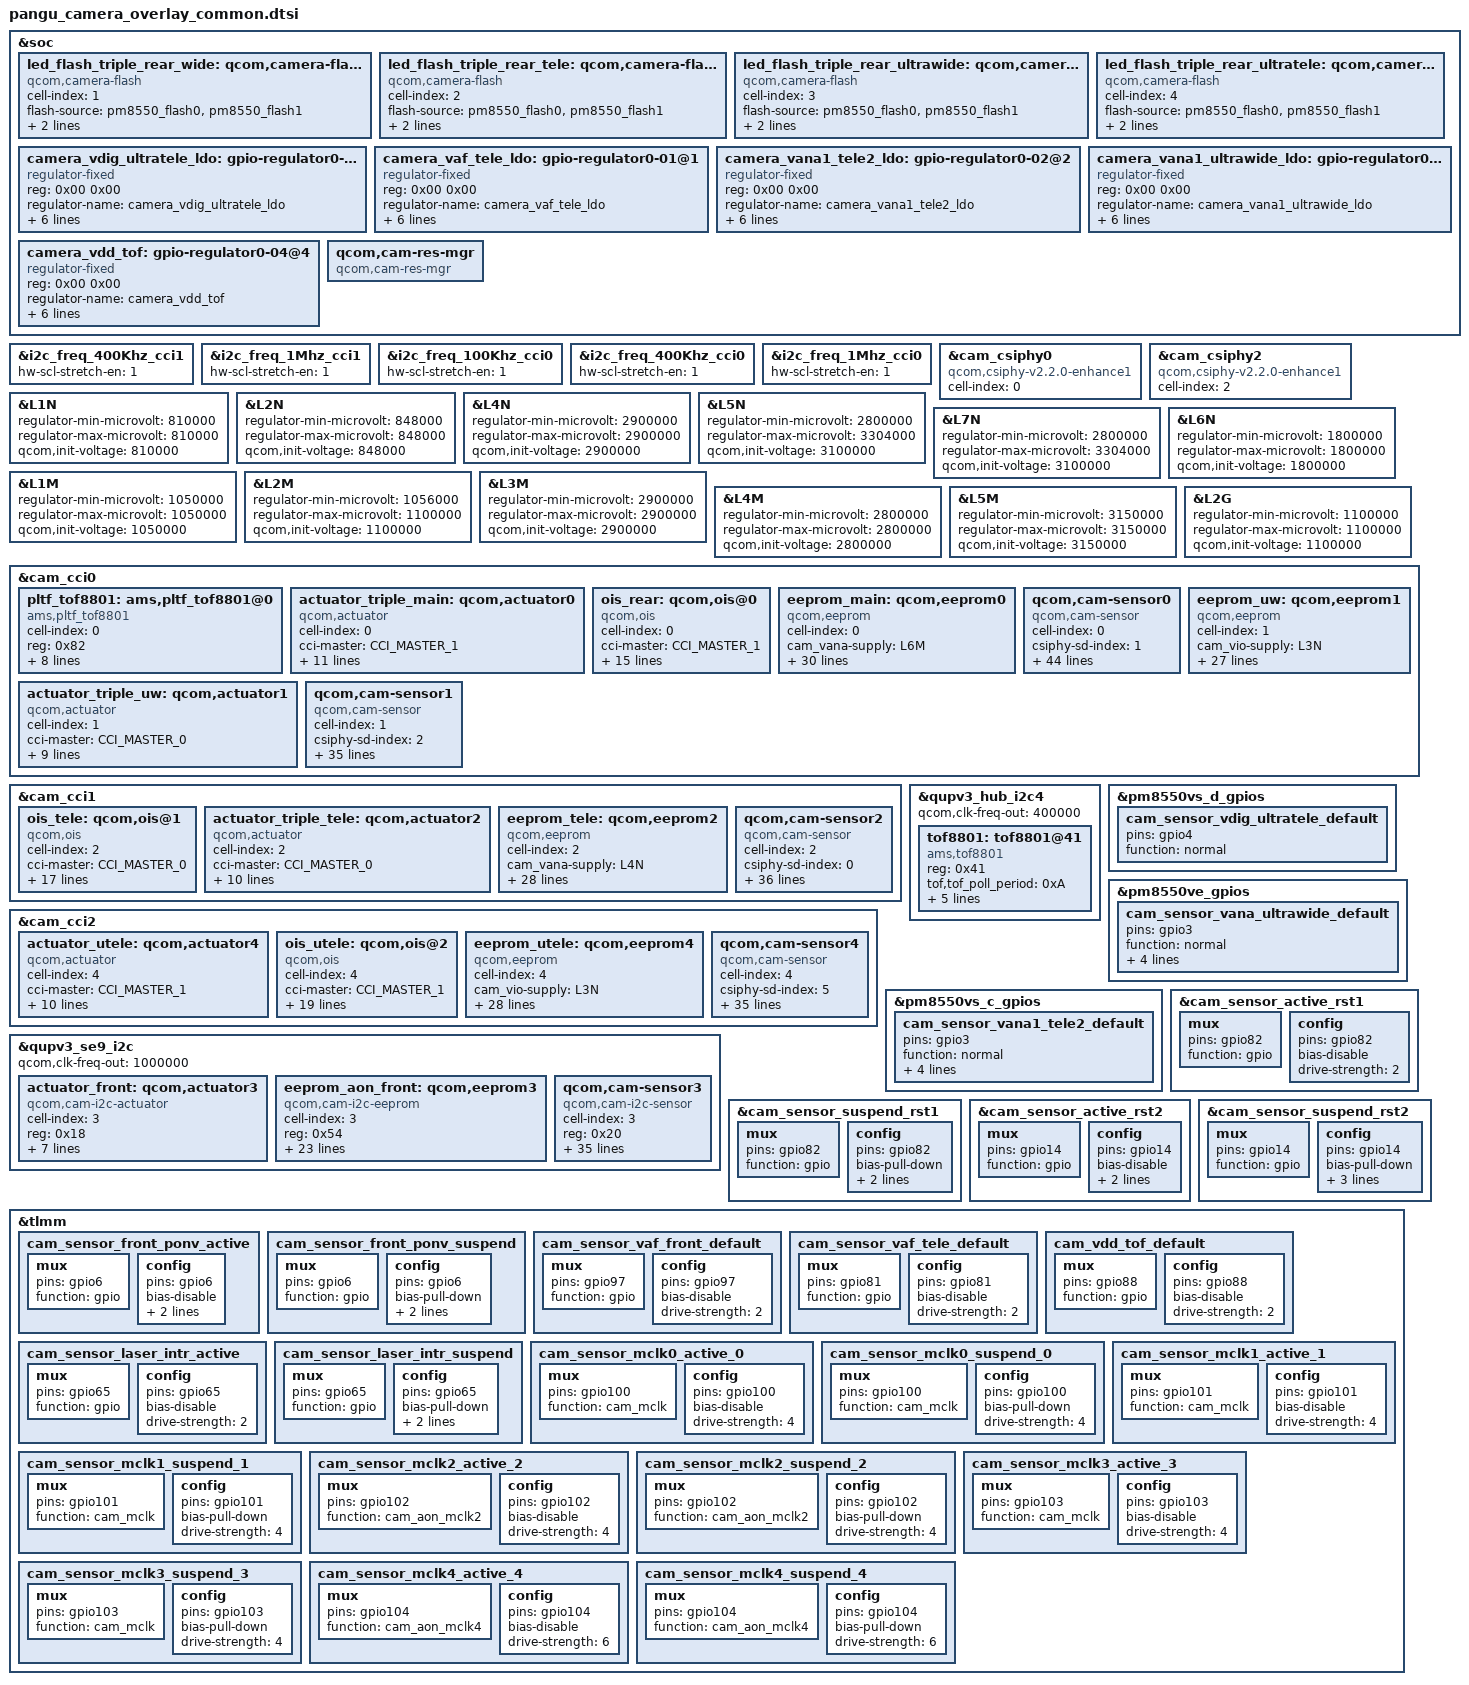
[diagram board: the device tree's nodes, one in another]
#include <dt-bindings/msm-camera.h>

&soc {
	led_flash_triple_rear_wide: qcom,camera-flash1 {
		cell-index = <1>;
		compatible = "qcom,camera-flash";
		flash-source = <&pm8550_flash0 &pm8550_flash1>;
		torch-source = <&pm8550_torch0 &pm8550_torch1>;
		switch-source = <&pm8550_switch2>;
		status = "ok";
	};

	led_flash_triple_rear_tele: qcom,camera-flash2 {
		cell-index = <2>;
		compatible = "qcom,camera-flash";
		flash-source = <&pm8550_flash0 &pm8550_flash1>;
		torch-source = <&pm8550_torch0 &pm8550_torch1>;
		switch-source = <&pm8550_switch2>;
		status = "ok";
	};

	led_flash_triple_rear_ultrawide: qcom,camera-flash3 {
		cell-index = <3>;
		compatible = "qcom,camera-flash";
		flash-source = <&pm8550_flash0 &pm8550_flash1>;
		torch-source = <&pm8550_torch0 &pm8550_torch1>;
		switch-source = <&pm8550_switch2>;
		status = "ok";
	};

	led_flash_triple_rear_ultratele: qcom,camera-flash4 {
		cell-index = <4>;
		compatible = "qcom,camera-flash";
		flash-source = <&pm8550_flash0 &pm8550_flash1>;
		torch-source = <&pm8550_torch0 &pm8550_torch1>;
		switch-source = <&pm8550_switch2>;
		status = "ok";
	};

	camera_vdig_ultratele_ldo: gpio-regulator0-00@0 {
		compatible = "regulator-fixed";
		reg = <0x00 0x00>;
		regulator-name = "camera_vdig_ultratele_ldo";
		regulator-min-microvolt = <1100000>;
		regulator-max-microvolt = <1100000>;
		regulator-enable-ramp-delay = <135>;
		enable-active-high;
		gpio = <&pm8550vs_d_gpios 4 0>;
		pinctrl-names = "default";
		pinctrl-0 = <&cam_sensor_vdig_ultratele_default>;
    };

	camera_vaf_tele_ldo: gpio-regulator0-01@1 {
		compatible = "regulator-fixed";
		reg = <0x00 0x00>;
		regulator-name = "camera_vaf_tele_ldo";
		regulator-min-microvolt = <2800000>;
		regulator-max-microvolt = <2800000>;
		regulator-enable-ramp-delay = <135>;
		enable-active-high;
		gpio = <&tlmm 81 0>;
		pinctrl-names = "default";
		pinctrl-0 = <&cam_sensor_vaf_tele_default>;
		//vin-supply = <&S6G>;
    };


	camera_vana1_tele2_ldo: gpio-regulator0-02@2 {
		compatible = "regulator-fixed";
		reg = <0x00 0x00>;
		regulator-name = "camera_vana1_tele2_ldo";
		regulator-min-microvolt = <1800000>;
		regulator-max-microvolt = <1800000>;
		regulator-enable-ramp-delay = <135>;
		enable-active-high;
		gpio = <&pm8550vs_c_gpios 3 0>;
		pinctrl-names = "default";
		pinctrl-0 = <&cam_sensor_vana1_tele2_default>;
	};
	
	camera_vana1_ultrawide_ldo: gpio-regulator0-03@3 {
		compatible = "regulator-fixed";
		reg = <0x00 0x00>;
		regulator-name = "camera_vana1_ultrawide_ldo";
		regulator-min-microvolt = <1800000>;
		regulator-max-microvolt = <1800000>;
		regulator-enable-ramp-delay = <135>;
		enable-active-high;
		gpio = <&pm8550ve_gpios 3 0>;
		pinctrl-names = "default";
		pinctrl-0 = <&cam_sensor_vana_ultrawide_default>;
	};

	camera_vdd_tof: gpio-regulator0-04@4 {
		compatible = "regulator-fixed";
		reg = <0x00 0x00>;
		regulator-name = "camera_vdd_tof";
		regulator-min-microvolt = <2800000>;
		regulator-max-microvolt = <2800000>;
		regulator-enable-ramp-delay = <135>;
		enable-active-high;
		gpio = <&tlmm 88 0>;
		pinctrl-names = "default";
		pinctrl-0 = <&cam_vdd_tof_default>;
    };

	qcom,cam-res-mgr {
		compatible = "qcom,cam-res-mgr";
		status = "ok";
	};
};
&i2c_freq_400Khz_cci1 {
    hw-scl-stretch-en = <1>;
};

&i2c_freq_1Mhz_cci1 {
    hw-scl-stretch-en = <1>;
};

&i2c_freq_100Khz_cci0 {
    hw-scl-stretch-en = <1>;
};

&i2c_freq_400Khz_cci0 {
    hw-scl-stretch-en = <1>;
};

&i2c_freq_1Mhz_cci0 {
    hw-scl-stretch-en = <1>;
};

&cam_csiphy0{
	cell-index = <0>;
	compatible = "qcom,csiphy-v2.2.0-enhance1", "qcom,csiphy";
};
&cam_csiphy2{
	cell-index = <2>;
	compatible = "qcom,csiphy-v2.2.0-enhance1", "qcom,csiphy";
};

&L1N {
  regulator-min-microvolt = <810000>;
  regulator-max-microvolt = <810000>;
  qcom,init-voltage = <810000>;
};

&L2N {
  regulator-min-microvolt = <848000>;
  regulator-max-microvolt = <848000>;
  qcom,init-voltage = <848000>;
};

&L4N {
  regulator-min-microvolt = <2900000>;
  regulator-max-microvolt = <2900000>;
  qcom,init-voltage = <2900000>;
};

&L5N {
  regulator-min-microvolt = <2800000>;
  regulator-max-microvolt = <3304000>;
  qcom,init-voltage = <3100000>;
};

&L7N {
  regulator-min-microvolt = <2800000>;
  regulator-max-microvolt = <3304000>;
  qcom,init-voltage = <3100000>;
};

&L6N {
  regulator-min-microvolt = <1800000>;
  regulator-max-microvolt = <1800000>;
  qcom,init-voltage = <1800000>;
};

&L1M {
  regulator-min-microvolt = <1050000>;
  regulator-max-microvolt = <1050000>;
  qcom,init-voltage = <1050000>;
};

&L2M {
  regulator-min-microvolt = <1056000>;
  regulator-max-microvolt = <1100000>;
  qcom,init-voltage = <1100000>;
};

&L3M {
  regulator-min-microvolt = <2900000>;
  regulator-max-microvolt = <2900000>;
  qcom,init-voltage = <2900000>;
};

&L4M {
  regulator-min-microvolt = <2800000>;
  regulator-max-microvolt = <2800000>;
  qcom,init-voltage = <2800000>;
};

&L5M {
  regulator-min-microvolt = <3150000>;
  regulator-max-microvolt = <3150000>;
  qcom,init-voltage = <3150000>;
};

&L2G {
  regulator-min-microvolt = <1100000>;
  regulator-max-microvolt = <1100000>;
  qcom,init-voltage = <1100000>;
};

&cam_cci0 {

     pltf_tof8801: ams,pltf_tof8801@0 {
         cell-index = <0>;
         reg = <0x82>;
         compatible = "ams,pltf_tof8801";
         cam_vio-supply = <&L3N>;
         cam_vana-supply = <&camera_vdd_tof>;
         regulator-names = "cam_vio", "cam_vana";
         rgltr-cntrl-support;
        rgltr-min-voltage = <1800000 2800000>;
        rgltr-max-voltage = <1800000 2800000>;
        rgltr-load-current = <600000 300000>;
         cci-master = <CCI_MASTER_1>;
         status = "ok";
     };

	actuator_triple_main: qcom,actuator0 {
		cell-index = <0>;
		compatible = "qcom,actuator";
		cci-master = <CCI_MASTER_1>;
		cam_vio-supply = <&L3N>;
		cam_vaf-supply = <&L5M>;
		regulator-names = "cam_vio", "cam_vaf";
		rgltr-cntrl-support;
		rgltr-min-voltage = <1800000 3150000>;
		rgltr-max-voltage = <1800000 3150000>;
		rgltr-load-current = <600000 300000>;
		reactive-ctrl-support;
		//                       reg_addr   addr_type   reg_data    data_type   delay       data_mask
		reactive-reg-setting = < 0x02       1           0x00        1           2800        0x00 >;
		actuator,name = "ak7316";
		is_af_parklens = <1>;
		status = "ok";
	};

	ois_rear: qcom,ois@0{
		cell-index = <0>;
		compatible = "qcom,ois";
		cci-master = <CCI_MASTER_1>;
		cam_vio-supply = <&L3N>;
		cam_vaf-supply = <&L5M>;
		cam_v_custom2-supply = <&L7M>;
		regulator-names = "cam_vio", "cam_vaf","cam_v_custom2";
		rgltr-cntrl-support;
		rgltr-min-voltage = <1800000 3150000 3150000>;
		rgltr-max-voltage = <1800000 3150000 3150000>;
		rgltr-load-current = <600000 300000 300000>;
		ois_gyro,position=<3>;
		ois_gyro,type=<3>;
		ois,type=<0>;
		//ois,name="bu63169";//??
		ois_module,vendor=<1>;
		ois_actuator,vednor=<2>;
		ois,fw=<1>;
		status = "ok";
	};

	eeprom_main: qcom,eeprom0 {
		cell-index = <0>;
		compatible = "qcom,eeprom";
		cam_vana-supply = <&L6M>;
		cam_v_custom1-supply = <&L3M>;
		cam_vdig-supply = <&L1M>;
		cam_vio-supply = <&L3N>;
		cam_vaf-supply = <&L5M>;
		cam_v_custom2-supply = <&L7M>;
		cam_clk-supply = <&cam_cc_titan_top_gdsc>;
		regulator-names = "cam_vana", "cam_v_custom1", "cam_vdig", "cam_vio", "cam_vaf", "cam_v_custom2",
		                  "cam_clk";
		rgltr-cntrl-support;
		rgltr-min-voltage = <1800000 2900000 1050000 1800000 3150000 3150000 0>;
		rgltr-max-voltage = <1800000 2900000 1050000 1800000 3150000 3150000 0>;
		rgltr-load-current = <300000 600000 1200000 600000 300000 300000 0>;
		gpio-no-mux = <0>;
		pinctrl-names = "cam_default", "cam_suspend";
		pinctrl-0 = <&cam_sensor_mclk1_active_1
			&cam_sensor_active_rst1>;
		pinctrl-1 = <&cam_sensor_mclk1_suspend_1
			&cam_sensor_suspend_rst1>;
		gpios = <&tlmm 101 0>,
			<&tlmm 82 0>;
		gpio-reset = <1>;
		gpio-req-tbl-num = <0 1>;
		gpio-req-tbl-flags = <1 0>;
		gpio-req-tbl-label = "CAMIF_MCLK1",
					"CAM_RESET1";
		cci-master = <CCI_MASTER_1>;
		clocks = <&camcc CAM_CC_MCLK1_CLK>;
		clock-names = "cam_clk";
		clock-cntl-level = "nominal";
		clock-rates = <19200000>;
		status = "ok";
	};

    //main camera
	qcom,cam-sensor0 {
		cell-index = <0>;
		compatible = "qcom,cam-sensor";
		csiphy-sd-index = <1>;
		sensor-position-roll = <90>;
		sensor-position-pitch = <0>;
		sensor-position-yaw = <180>;
		eeprom-src = <&eeprom_main>;
		actuator-src = <&actuator_triple_main>;
		ois-src = <&ois_rear>;
		led-flash-src = <&led_flash_triple_rear_wide>;
		cam_vana-supply = <&L6M>;
		cam_v_custom1-supply = <&L3M>;
		cam_vdig-supply = <&L1N>;
		cam_vio-supply = <&L3N>;
		cam_vaf-supply = <&L5M>;
		cam_v_custom2-supply = <&L7M>;
		cam_clk-supply = <&cam_cc_titan_top_gdsc>;
		regulator-names = "cam_vana", "cam_v_custom1", "cam_vdig", "cam_vio", "cam_vaf", "cam_v_custom2",
		                  "cam_clk";
		rgltr-cntrl-support;
		rgltr-min-voltage = <1800000 2900000 810000 1800000 3150000 3150000 0>;
		rgltr-max-voltage = <1800000 2900000 810000 1800000 3150000 3150000 0>;
		rgltr-load-current = <300000 600000 1200000 600000  300000  300000  0>;
		gpio-no-mux = <0>;
		pinctrl-names = "cam_default", "cam_suspend";
		pinctrl-0 = <&cam_sensor_mclk1_active_1
			&cam_sensor_active_rst1>;
		pinctrl-1 = <&cam_sensor_mclk1_suspend_1
			&cam_sensor_suspend_rst1>;
		gpios = <&tlmm 101 0>,
			<&tlmm 82 0>;
		gpio-reset = <1>;
		gpio-req-tbl-num = <0 1>;
		gpio-req-tbl-flags = <1 0>;
		gpio-req-tbl-label = "CAMIF_MCLK1",
					"CAM_RESET1";
		cci-master = <CCI_MASTER_1>;
		clocks = <&camcc CAM_CC_MCLK1_CLK>;
		clock-names = "cam_clk";
		clock-cntl-level = "nominal";
		clock-rates = <19200000>;
		is-support-laser = <1>;
		enable_qsc_write_in_advance = <1>;
		qsc_reg_addr = <0x24C0>;
		eeprom_slave_addr = <0xA2>;
		qsc_data_size = <2304>;
		write_qsc_addr = <0x5800>;
		status = "ok";
	};

	actuator_triple_uw: qcom,actuator1 {
		cell-index = <1>;
		compatible = "qcom,actuator";
		cci-master = <CCI_MASTER_0>;
		cam_vio-supply = <&L3N>;
		cam_vaf-supply = <&L4M>;
		regulator-names = "cam_vio","cam_vaf";
		rgltr-cntrl-support;
		rgltr-min-voltage = <1800000 2800000>;
		rgltr-max-voltage = <1800000 2800000>;
		rgltr-load-current = <600000 600000>;
		is_update_pid;
		actuator,name = "dw9827c";
		status = "ok";
	};

	eeprom_uw: qcom,eeprom1 {
		cell-index = <1>;
		compatible = "qcom,eeprom";
		cam_vio-supply = <&L3N>;
		cam_vana-supply = <&camera_vana1_ultrawide_ldo>;
		cam_vaf-supply = <&L4M>;
		cam_vdig-supply = <&L1M>;
		cam_clk-supply = <&cam_cc_titan_top_gdsc>;
		regulator-names = "cam_vio", "cam_vana",
			"cam_vaf","cam_vdig", "cam_clk";
		rgltr-cntrl-support;
		rgltr-min-voltage = <1800000 1800000 2800000 1050000 0>;
		rgltr-max-voltage = <1800000 1800000 2800000 1050000 0>;
		rgltr-load-current = <600000 300000 600000 1200000 0>;
		gpio-no-mux = <0>;
		pinctrl-names = "cam_default", "cam_suspend";
		pinctrl-0 = <&cam_sensor_mclk2_active_2
				 &cam_sensor_active_rst2>;
		pinctrl-1 = <&cam_sensor_mclk2_suspend_2
				 &cam_sensor_suspend_rst2>;
		gpios = <&tlmm 102 0>,
			<&tlmm 14 0>;
		gpio-reset = <1>;
		gpio-req-tbl-num = <0 1>;
		gpio-req-tbl-flags = <1 0>;
		gpio-req-tbl-label = "CAMIF_MCLK2",
					"CAM_RESET2";
		cci-master = <CCI_MASTER_0>;
		clocks = <&camcc CAM_CC_MCLK2_CLK>;
		clock-names = "cam_clk";
		clock-cntl-level = "nominal";
		clock-rates = <19200000>;
		status = "ok";
	};

    //wide camera
	qcom,cam-sensor1 {
		cell-index = <1>;
		compatible = "qcom,cam-sensor";
		csiphy-sd-index = <2>;
		sensor-position-roll = <90>;
		sensor-position-pitch = <0>;
		sensor-position-yaw = <180>;
		eeprom-src = <&eeprom_uw>;
		actuator-src = <&actuator_triple_uw>;
		led-flash-src = <&led_flash_triple_rear_ultrawide>;
		cam_vio-supply = <&L3N>;
		cam_vana-supply = <&camera_vana1_ultrawide_ldo>;
		cam_vaf-supply = <&L4M>;
		cam_vdig-supply = <&L1M>;
		cam_clk-supply = <&cam_cc_titan_top_gdsc>;
		regulator-names = "cam_vio", "cam_vana",
			"cam_vaf","cam_vdig", "cam_clk";
		rgltr-cntrl-support;
		rgltr-min-voltage = <1800000 1800000 2800000 1050000 0>;
		rgltr-max-voltage = <1800000 1800000 2800000 1050000 0>;
		rgltr-load-current = <600000 300000 600000 1200000 0>;
		gpio-no-mux = <0>;
		pinctrl-names = "cam_default", "cam_suspend";
		pinctrl-0 = <&cam_sensor_mclk2_active_2
				 &cam_sensor_active_rst2>;
		pinctrl-1 = <&cam_sensor_mclk2_suspend_2
				 &cam_sensor_suspend_rst2>;
		gpios = <&tlmm 102 0>,
			<&tlmm 14 0>;
		gpio-reset = <1>;
		gpio-req-tbl-num = <0 1>;
		gpio-req-tbl-flags = <1 0>;
		gpio-req-tbl-label = "CAMIF_MCLK2",
					"CAM_RESET2";
		cci-master = <CCI_MASTER_0>;
		clocks = <&camcc CAM_CC_MCLK2_CLK>;
		clock-names = "cam_clk";
		clock-cntl-level = "nominal";
		clock-rates = <19200000>;
		change_wide_af_sleep = <1>;//change to wide af default sleep mode to reduce power
		status = "ok";
	};

};
&cam_cci1 {
	ois_tele: qcom,ois@1{
		cell-index = <2>;
		compatible = "qcom,ois";
		cci-master = <CCI_MASTER_0>;
		cam_vio-supply = <&L3N>;
		cam_vaf-supply = <&camera_vaf_tele_ldo>;
		regulator-names = "cam_vio", "cam_vaf";
		rgltr-cntrl-support;
		rgltr-min-voltage = <1800000 2800000>;
		rgltr-max-voltage = <1800000 2800000>;
		rgltr-load-current = <600000 600000>;
		ois_gyro,position=<3>;
		ois_gyro,type=<0>;
		ois,type=<1>;
		ois,name="bu24721";
		ois_module,vendor=<1>;
		ois_actuator,vednor=<2>;
		ois,fw=<1>;
		download,fw=<1>;
		ois_eis_function = <5>;
		actuator_ois_eeprom_merge = <1>;
		status = "ok";
	};

	actuator_triple_tele: qcom,actuator2{
		cell-index = <2>;
		compatible = "qcom,actuator";
		cci-master = <CCI_MASTER_0>;
		cam_vio-supply = <&L3N>;
		cam_vaf-supply = <&camera_vaf_tele_ldo>;
		regulator-names = "cam_vio", "cam_vaf";
		rgltr-cntrl-support;
		rgltr-min-voltage = <1800000 2800000>;
		rgltr-max-voltage = <1800000 2800000>;
		rgltr-load-current = <600000 600000>;
		reactive-ctrl-support;
		//                       reg_addr   addr_type   reg_data    data_type   delay       data_mask
		reactive-reg-setting = < 0x02       1           0x00        1           2800        0x00 >;
		actuator,name = "ak7316";
		status = "ok";
	};
	eeprom_tele: qcom,eeprom2 {
		cell-index = <2>;
		compatible = "qcom,eeprom";
		cam_vana-supply = <&L4N>;
		cam_vdig-supply = <&L2M>;
		cam_vio-supply = <&L3N>;
		cam_vaf-supply = <&camera_vaf_tele_ldo>;
		cam_clk-supply = <&cam_cc_titan_top_gdsc>;
		regulator-names = "cam_vana", "cam_vdig", "cam_vio", "cam_vaf",
		                  "cam_clk";
		rgltr-cntrl-support;
		rgltr-min-voltage = <2900000 1100000 1800000 2800000 0>;
		rgltr-max-voltage = <2900000 1100000 1800000 2800000 0>;
		rgltr-load-current = <300000 1200000 600000 600000 0>;
		gpio-no-mux = <0>;
		pinctrl-names = "cam_default", "cam_suspend";
		pinctrl-0 = <&cam_sensor_mclk3_active_3
				 &cam_sensor_active_rst3>;
		pinctrl-1 = <&cam_sensor_mclk3_suspend_3
				 &cam_sensor_suspend_rst3>;
		gpios = <&tlmm 103 0>,
			<&tlmm 109 0>;
		gpio-reset = <1>;
		gpio-req-tbl-num = <0 1>;
		gpio-req-tbl-flags = <1 0>;
		gpio-req-tbl-label = "CAMIF_MCLK3",
					"CAM_RESET3";
		cci-master = <CCI_MASTER_0>;
		clocks = <&camcc CAM_CC_MCLK3_CLK>;
		clock-names = "cam_clk";
		clock-cntl-level = "nominal";
		clock-rates = <19200000>;
		actuator_ois_eeprom_merge = <1>;
		status = "ok";
	};
    //tele
	qcom,cam-sensor2 {
		cell-index = <2>;
		compatible = "qcom,cam-sensor";
		csiphy-sd-index = <0>;
		sensor-position-roll = <90>;
		sensor-position-pitch = <0>;
		sensor-position-yaw = <180>;
		eeprom-src = <&eeprom_tele>;
		ois-src = <&ois_tele>;
		actuator-src = <&actuator_triple_tele>;
		led-flash-src = <&led_flash_triple_rear_tele>;
		cam_vana-supply = <&L4N>;
		cam_vdig-supply = <&L2M>;
		cam_vio-supply = <&L3N>;
		cam_v_custom1-supply = <&L6N>;
		cam_vaf-supply = <&camera_vaf_tele_ldo>;
		cam_clk-supply = <&cam_cc_titan_top_gdsc>;
		regulator-names = "cam_vana", "cam_vdig", "cam_vio", "cam_v_custom1", "cam_vaf",
		                  "cam_clk";
		rgltr-cntrl-support;
		rgltr-min-voltage = <2900000 1100000 1800000 1800000 2800000 0>;
		rgltr-max-voltage = <2900000 1100000 1800000 1800000 2800000 0>;
		rgltr-load-current = <300000 1200000 600000 600000 600000 0>;
		gpio-no-mux = <0>;
		pinctrl-names = "cam_default", "cam_suspend";
		pinctrl-0 = <&cam_sensor_mclk3_active_3
				 &cam_sensor_active_rst3>;
		pinctrl-1 = <&cam_sensor_mclk3_suspend_3
				 &cam_sensor_suspend_rst3>;
		gpios = <&tlmm 103 0>,
			<&tlmm 109 0>;
		gpio-reset = <1>;
		gpio-req-tbl-num = <0 1>;
		gpio-req-tbl-flags = <1 0>;
		gpio-req-tbl-label = "CAMIF_MCLK3",
					"CAM_RESET3";
		cci-master = <CCI_MASTER_0>;
		clocks = <&camcc CAM_CC_MCLK3_CLK>;
		clock-names = "cam_clk";
		clock-cntl-level = "nominal";
		clock-rates = <19200000>;
		status = "ok";
	};

};

&cam_cci2{


	actuator_utele: qcom,actuator4{
		cell-index = <4>;
		compatible = "qcom,actuator";
		cci-master = <CCI_MASTER_1>;
		cam_vio-supply = <&L3N>;
		cam_vaf-supply = <&L7N>;
		cam_v_custom1-supply = <&L5N>;
		regulator-names = "cam_vio", "cam_vaf", "cam_v_custom1";

		rgltr-cntrl-support;
		rgltr-min-voltage = <1800000 3100000 3100000>;
		rgltr-max-voltage = <1800000 3100000 3100000>;
		rgltr-load-current = <600000 300000  300000>;			//????
		actuator,name = "dw9786";
		status = "ok";
	};

	ois_utele: qcom,ois@2{
		cell-index = <4>;
		compatible = "qcom,ois";
		cci-master = <CCI_MASTER_1>;
		cam_vio-supply = <&L3N>;
		cam_vaf-supply = <&L7N>;
		cam_v_custom1-supply = <&L5N>;
		regulator-names = "cam_vio","cam_vaf","cam_v_custom1";
		rgltr-cntrl-support;
		rgltr-min-voltage = <1800000 3100000 3100000>;
		rgltr-max-voltage = <1800000 3100000 3100000>;
		rgltr-load-current = <600000 300000  300000>;			//????
		ois_gyro,position=<3>;
		ois_gyro,type=<0>;
		ois,type=<1>;
		ois,name="dw9786";
		ois_module,vendor=<1>;
		ois_actuator,vednor=<2>;
		ois,fw=<1>;
		download,fw=<1>;
		ois_eis_function = <7>;
		ois_switch_spi_mode=<1>;
		status = "ok";
	};

	eeprom_utele: qcom,eeprom4 {
		cell-index = <4>;
		compatible = "qcom,eeprom";
		cam_vio-supply = <&L3N>;
		cam_vana-supply = <&camera_vana1_tele2_ldo>;
		cam_vdig-supply = <&camera_vdig_ultratele_ldo>;
		cam_vaf-supply = <&L7N>;
		cam_v_custom1-supply = <&L5N>;
		cam_clk-supply = <&cam_cc_titan_top_gdsc>;
		regulator-names = "cam_vio", "cam_vdig", "cam_vana", "cam_vaf", "cam_v_custom1", "cam_clk";
		rgltr-cntrl-support;
		rgltr-min-voltage = <1800000 1100000 1800000 3100000 3100000 0>;
		rgltr-max-voltage = <1800000 1100000 1800000 3100000 3100000 0>;
		rgltr-load-current = <600000 1200000 300000 300000 300000 0>;		//????
		gpio-no-mux = <0>;
		pinctrl-names = "cam_default", "cam_suspend";
		pinctrl-0 = <&cam_sensor_mclk0_active_0
				 &cam_sensor_active_rst5>;
		pinctrl-1 = <&cam_sensor_mclk0_suspend_0
				 &cam_sensor_suspend_rst5>;
		gpios = <&tlmm 100 0>,
			<&tlmm 110 0>;
		gpio-reset = <1>;
//		gpio-custom1 = <2>;
		gpio-req-tbl-num = <0 1>;
		gpio-req-tbl-flags = <1 0>;
		gpio-req-tbl-label = "CAMIF_MCLK0",
					"CAM_RESET5";
		cci-master = <CCI_MASTER_1>;
		clocks = <&camcc CAM_CC_MCLK0_CLK>;
		clock-names = "cam_clk";
		clock-cntl-level = "nominal";
		clock-rates = <19200000>;
		status = "ok";
	};

	//tele2
	qcom,cam-sensor4 {
		cell-index = <4>;
		compatible = "qcom,cam-sensor";
		csiphy-sd-index = <5>;		//????
		sensor-position-roll = <90>;
		sensor-position-pitch = <0>;
		sensor-position-yaw = <180>;
		eeprom-src = <&eeprom_utele>;
		ois-src = <&ois_utele>;
		actuator-src = <&actuator_utele>;
		led-flash-src = <&led_flash_triple_rear_ultratele>;
		cam_vio-supply = <&L3N>;
		cam_vana-supply = <&camera_vana1_tele2_ldo>;
		cam_vdig-supply = <&camera_vdig_ultratele_ldo>;
		cam_vaf-supply = <&L7N>;
		cam_clk-supply = <&cam_cc_titan_top_gdsc>;
		regulator-names = "cam_vio", "cam_vdig", "cam_vana", "cam_vaf", "cam_clk";
		rgltr-cntrl-support;
		rgltr-min-voltage = <1800000 1100000 1800000 3100000 0>;
		rgltr-max-voltage = <1800000 1100000 1800000 3100000 0>;
		rgltr-load-current = <600000 1200000 300000 300000 0>;		//????
		gpio-no-mux = <0>;
		pinctrl-names = "cam_default", "cam_suspend";
		pinctrl-0 = <&cam_sensor_mclk0_active_0
				 &cam_sensor_active_rst5>;
		pinctrl-1 = <&cam_sensor_mclk0_suspend_0
				 &cam_sensor_suspend_rst5>;
		gpios = <&tlmm 100 0>,
			<&tlmm 110 0>;
		gpio-reset = <1>;
//		gpio-custom1 = <2>;
		gpio-req-tbl-num = <0 1>;
		gpio-req-tbl-flags = <1 0>;
		gpio-req-tbl-label = "CAMIF_MCLK0",
					"CAM_RESET5";
		cci-master = <CCI_MASTER_1>;		//????
		clocks = <&camcc CAM_CC_MCLK0_CLK>;
		clock-names = "cam_clk";
		clock-cntl-level = "nominal";
		clock-rates = <19200000>;
		status = "ok";
	};
	
};

&qupv3_se9_i2c {
    status = "ok";
    qcom,clk-freq-out = <1000000>;
	actuator_front: qcom,actuator3{
		cell-index = <3>;
		reg = <0x18>;  //slave address >> 1
		compatible = "qcom,cam-i2c-actuator";
		cam_vio-supply = <&L3N>;
		cam_vaf-supply = <&L4M>;
		regulator-names = "cam_vio", "cam_vaf";
		rgltr-cntrl-support;
		rgltr-min-voltage = <1800000 2800000>;
		rgltr-max-voltage = <1800000 2800000>;
		rgltr-load-current = <600000 300000>;
		status = "ok";
	};
	eeprom_aon_front: qcom,eeprom3 {
		cell-index = <3>; 
		reg = <0x54>;
		compatible = "qcom,cam-i2c-eeprom";
		cam_vana-supply = <&L4N>;
		cam_vdig-supply = <&L2N>;
		cam_vio-supply = <&L3N>;
		cam_clk-supply = <&cam_cc_titan_top_gdsc>;
		regulator-names = "cam_vana", "cam_vdig", "cam_vio", "cam_clk";
		rgltr-cntrl-support;
		rgltr-min-voltage = <2900000 848000 1800000 0>;
		rgltr-max-voltage = <2900000 848000 1800000 0>;
		rgltr-load-current = <300000 1200000 600000 0>;
		gpio-no-mux = <0>;
		pinctrl-names = "cam_default", "cam_suspend";
		pinctrl-0 = <&cam_sensor_mclk4_active_4
				 &cam_sensor_active_rst4>;
		pinctrl-1 = <&cam_sensor_mclk4_suspend_4
				 &cam_sensor_suspend_rst4>;
		gpios = <&tlmm 104 0>,
			<&tlmm 7 0>;
		gpio-reset = <1>;
		gpio-req-tbl-num = <0 1>;
		gpio-req-tbl-flags = <1 0>;
		gpio-req-tbl-label = "CAMIF_MCLK4",
					"CAM_RESET4";
		clocks = <&camcc CAM_CC_MCLK4_CLK>;
		clock-names = "cam_clk";
		clock-cntl-level = "nominal";
		clock-rates = <19200000>;
		status = "ok";
	};

	qcom,cam-sensor3 {
		cell-index = <3>;
		reg = <0x20>;
		compatible =  "qcom,cam-i2c-sensor";
		csiphy-sd-index = <4>;
		sensor-position-roll = <270>;
		sensor-position-pitch = <0>;
		sensor-position-yaw = <180>;
		eeprom-src = <&eeprom_aon_front>;
		actuator-src = <&actuator_front>;
		cam_vana-supply = <&L4N>;
		cam_vdig-supply = <&L2N>;
		cam_vio-supply = <&L3N>;
		cam_clk-supply = <&cam_cc_titan_top_gdsc>;
		regulator-names = "cam_vana", "cam_vdig", "cam_vio","cam_vaf","cam_clk";
		rgltr-cntrl-support;
		aon-camera-id = <AON_CAM1>;
		rgltr-min-voltage = <2900000 848000 1800000 2800000 0>;
		rgltr-max-voltage = <2900000 848000 1800000 2800000 0>;
		rgltr-load-current = <300000 1200000 600000 300000 0>;
		gpio-no-mux = <0>;
		pinctrl-names = "cam_default", "cam_suspend";
		pinctrl-0 = <&cam_sensor_mclk4_active_4
				 &cam_sensor_active_rst4
				 &cam_sensor_front_ponv_active>;
		pinctrl-1 = <&cam_sensor_mclk4_suspend_4
				 &cam_sensor_suspend_rst4
				 &cam_sensor_front_ponv_suspend>;
		gpios = <&tlmm 104 0>,
			<&tlmm 7 0>;
		gpio-reset = <1>;
		gpio-req-tbl-num = <0 1>;
		gpio-req-tbl-flags = <1 0>;
		gpio-req-tbl-label = "CAMIF_MCLK4",
					"CAM_RESET4";
		clocks = <&camcc CAM_CC_MCLK4_CLK>;
		clock-names = "cam_clk";
		clock-cntl-level = "nominal";
		clock-rates = <19200000>;
		status = "ok";
	};

};

&qupv3_hub_i2c4{
    status = "ok";
    qcom,clk-freq-out = <400000>;
    tof8801: tof8801@41 {
        reg = <0x41>;
        tof,tof_poll_period = <0xA>; /*poll period (100 usec)*/
        compatible = "ams,tof8801";
        pinctrl-names = "laser_default", "laser_suspend";
        pinctrl-0 = <&cam_sensor_laser_intr_active>;
        pinctrl-1 = <&cam_sensor_laser_intr_suspend>;
        interrupt-parent = <&tlmm>;
        enable-gpios = <&pm8550ve_gpios 6 0>;
        irq-gpios = <&tlmm 65 0>;
        status = "ok";
    };
};

&pm8550vs_d_gpios {
	cam_sensor_vdig_ultratele_default: cam_sensor_vdig_ultratele_default {
		pins = "gpio4";
		function = "normal";
	};
};

&pm8550ve_gpios {
	cam_sensor_vana_ultrawide_default: cam_sensor_vana_ultrawide_default {
		pins = "gpio3";
		function = "normal";
		input-disable;
		output-low;
		power-source = <1>; /* 1.8V */
		qcom,drive-strength = <2>;
	};
};

&pm8550vs_c_gpios {
		cam_sensor_vana1_tele2_default: cam_sensor_vana1_tele2_default {
			pins = "gpio3";
			function = "normal";
			input-disable;
			output-low;
			power-source = <1>; /* 1.8V */
			qcom,drive-strength = <2>;
		};
};
&cam_sensor_active_rst1 {
		mux {
			pins = "gpio82";
			function = "gpio";
		};

		config {
			pins = "gpio82";
			bias-disable; /* No PULL */
			drive-strength = <2>; /* 2 MA */
		};
	};

&cam_sensor_suspend_rst1 {
	mux {
		pins = "gpio82";
		function = "gpio";
	};

	config {
		pins = "gpio82";
		bias-pull-down; /* PULL DOWN */
		drive-strength = <2>; /* 2 MA */
		output-low;
	};
};

&cam_sensor_active_rst2 {
	mux {
		pins = "gpio14";
		function = "gpio";
	};

	config {
		pins = "gpio14";
		bias-disable; /* No PULL */
		drive-strength = <2>; /* 2 MA */
		qcom,apps;
	};
};

&cam_sensor_suspend_rst2 {
	mux {
		pins = "gpio14";
		function = "gpio";
	};

	config {
		pins = "gpio14";
		bias-pull-down; /* PULL DOWN */
		drive-strength = <2>; /* 2 MA */
		output-low;
		qcom,remote;
	};
};
&tlmm {
	cam_sensor_front_ponv_active: cam_sensor_front_ponv_active {
		/* PONV */
		mux {
			pins = "gpio6";
			function = "gpio";
		};

		config {
			pins = "gpio6";
			bias-disable; /* No PULL */
			output-high;
			drive-strength = <6>; /* 2 MA */
		};
	};

	cam_sensor_front_ponv_suspend: cam_sensor_front_ponv_suspend {
		/* PONV */
		mux {
			pins = "gpio6";
			function = "gpio";
		};

		config {
			pins = "gpio6";


			bias-pull-down; /* PULL DOWN */
			output-low;
			drive-strength = <6>; /* 2 MA */
		};
	};

	cam_sensor_vaf_front_default: cam_sensor_vaf_front_default {
		/*  VIO LDO */
		mux {
			pins = "gpio97";
			function = "gpio";
		};

		config {
			pins = "gpio97";
			bias-disable; /* No PULL */
			drive-strength = <2>; /* 2 MA */
		};
	};
	
	cam_sensor_vaf_tele_default:cam_sensor_vaf_tele_default {
		/*  VIO LDO */
		mux {
			pins = "gpio81";
			function = "gpio";
		};

		config {
			pins = "gpio81";
			bias-disable; /* No PULL */
			drive-strength = <2>; /* 2 MA */
		};
	};

	cam_vdd_tof_default:cam_vdd_tof_default {
		/*  VIO LDO */
		mux {
			pins = "gpio88";
			function = "gpio";
		};

		config {
			pins = "gpio88";
			bias-disable; /* No PULL */
			drive-strength = <2>; /* 2 MA */
		};
	};

     cam_sensor_laser_intr_active:cam_sensor_laser_intr_active {
        mux {
            pins = "gpio65";
            function = "gpio";
        };

        config {
            pins = "gpio65";
            bias-disable; /* No PULL */
            drive-strength = <2>; /* 2 MA */
        };
    };

    cam_sensor_laser_intr_suspend: cam_sensor_laser_intr_suspend {
        mux {
            pins = "gpio65";
            function = "gpio";
        };

        config {
            pins = "gpio65";
            bias-pull-down; /* PULL DOWN */
            drive-strength = <2>; /* 2 MA */
            output-low;
        };
    };
    cam_sensor_mclk0_active_0: cam_sensor_mclk0_active_0 {
        /* MCLK0 */
        mux {
            pins = "gpio100";
            function = "cam_mclk";
        };

        config {
            pins = "gpio100";
            bias-disable; /* No PULL */
            drive-strength = <4>; /* 2 MA */
        };
    };

    cam_sensor_mclk0_suspend_0: cam_sensor_mclk0_suspend_0 {
        /* MCLK0 */
        mux {
            pins = "gpio100";
            function = "cam_mclk";
        };

        config {
            pins = "gpio100";
            bias-pull-down; /* PULL DOWN */
            drive-strength = <4>; /* 2 MA */
        };
    };

    cam_sensor_mclk1_active_1: cam_sensor_mclk1_active_1 {
        /* MCLK1 */
        mux {
            pins = "gpio101";
            function = "cam_mclk";
        };

        config {
            pins = "gpio101";
            bias-disable; /* No PULL */
            drive-strength = <4>; /* 2 MA */
        };
    };

    cam_sensor_mclk1_suspend_1: cam_sensor_mclk1_suspend_1 {
        /* MCLK1 */
        mux {
            pins = "gpio101";
            function = "cam_mclk";
    };

        config {
            pins = "gpio101";
            bias-pull-down; /* PULL DOWN */
            drive-strength = <4>; /* 2 MA */
        };
    };

    cam_sensor_mclk2_active_2: cam_sensor_mclk2_active_2 {
        /* MCLK2 */
        mux {
            pins = "gpio102";
            function = "cam_aon_mclk2";
        };

        config {
            pins = "gpio102";
            bias-disable; /* No PULL */
            drive-strength = <4>; /* 2 MA */
        };
    };

    cam_sensor_mclk2_suspend_2: cam_sensor_mclk2_suspend_2 {
        /* MCLK2 */
        mux {
            pins = "gpio102";
            function = "cam_aon_mclk2";
        };

        config {
            pins = "gpio102";
            bias-pull-down; /* PULL DOWN */
            drive-strength = <4>; /* 2 MA */
        };
    };

    cam_sensor_mclk3_active_3: cam_sensor_mclk3_active_3 {
        /* MCLK3 */
        mux {
            pins = "gpio103";
            function = "cam_mclk";
        };

        config {
            pins = "gpio103";
            bias-disable; /* No PULL */
            drive-strength = <4>; /* 2 MA */
        };
    };

    cam_sensor_mclk3_suspend_3: cam_sensor_mclk3_suspend_3 {
        /* MCLK3 */
        mux {
            pins = "gpio103";
            function = "cam_mclk";
        };

        config {
            pins = "gpio103";
            bias-pull-down; /* PULL DOWN */
            drive-strength = <4>; /* 2 MA */
        };
    };

    cam_sensor_mclk4_active_4: cam_sensor_mclk4_active_4 {
        /* MCLK4 */
        mux {
            pins = "gpio104";
            function = "cam_aon_mclk4";
        };

        config {
            pins = "gpio104";
            bias-disable; /* No PULL */
            drive-strength = <6>; /* 2 MA */
        };
    };

    cam_sensor_mclk4_suspend_4: cam_sensor_mclk4_suspend_4 {
        /* MCLK4 */
        mux {
            pins = "gpio104";
            function = "cam_aon_mclk4";
        };

        config {
            pins = "gpio104";
            bias-pull-down; /* PULL DOWN */
            drive-strength = <6>; /* 2 MA */
        };
    };

};
